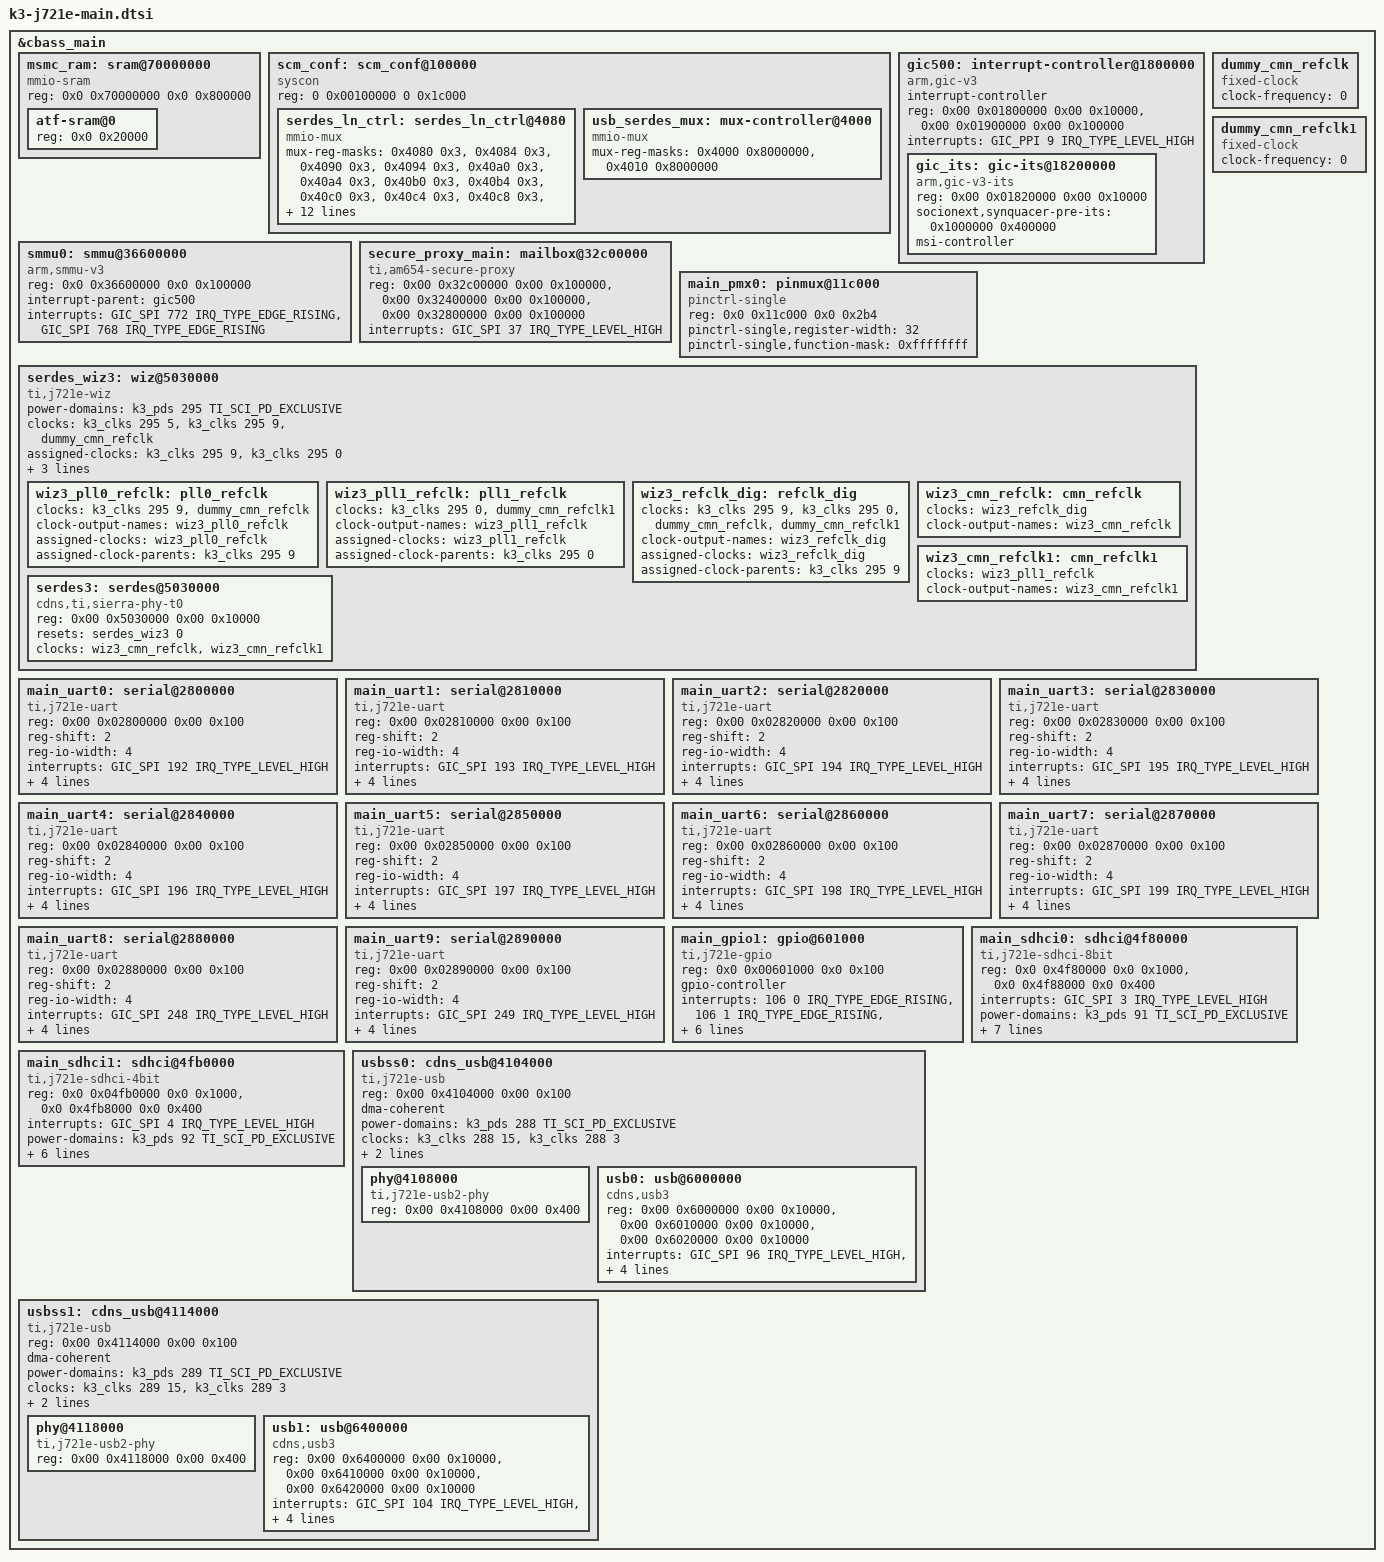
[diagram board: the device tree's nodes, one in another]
// SPDX-License-Identifier: GPL-2.0
/*
 * Device Tree Source for J721E SoC Family Main Domain peripherals
 *
 * Copyright (C) 2016-2019 Texas Instruments Incorporated - http://www.ti.com/
 */
#include <dt-bindings/mux/mux.h>
#include <dt-bindings/phy/phy.h>
#include <dt-bindings/mux/mux-j721e-wiz.h>

&cbass_main {
	msmc_ram: sram@70000000 {
		compatible = "mmio-sram";
		reg = <0x0 0x70000000 0x0 0x800000>;
		#address-cells = <1>;
		#size-cells = <1>;
		ranges = <0x0 0x0 0x70000000 0x800000>;

		atf-sram@0 {
			reg = <0x0 0x20000>;
		};
	};

	scm_conf: scm_conf@100000 {
		compatible = "syscon", "simple-mfd";
		reg = <0 0x00100000 0 0x1c000>;
		#address-cells = <1>;
		#size-cells = <1>;
		ranges = <0x0 0x0 0x00100000 0x1c000>;

		serdes_ln_ctrl: serdes_ln_ctrl@4080 {
			compatible = "mmio-mux";
			#mux-control-cells = <1>;
			mux-reg-masks = <0x4080 0x3>, <0x4084 0x3>, /* SERDES0 lane0/1 select */
					<0x4090 0x3>, <0x4094 0x3>, /* SERDES1 lane0/1 select */
					<0x40a0 0x3>, <0x40a4 0x3>, /* SERDES2 lane0/1 select */
					<0x40b0 0x3>, <0x40b4 0x3>, /* SERDES3 lane0/1 select */
					<0x40c0 0x3>, <0x40c4 0x3>, <0x40c8 0x3>, <0x40cc 0x3>;
					/* SERDES4 lane0/1/2/3 select */
			idle-states = <SERDES0_LANE0_PCIE0_LANE0>, <SERDES0_LANE1_PCIE0_LANE1>,
				      <SERDES1_LANE0_PCIE1_LANE0>, <SERDES1_LANE1_PCIE1_LANE1>,
				      <SERDES2_LANE0_PCIE2_LANE0>, <SERDES2_LANE1_PCIE2_LANE1>,
				      <MUX_IDLE_AS_IS>, <SERDES3_LANE1_USB3_0>,
				      <SERDES4_LANE0_EDP_LANE0>, <SERDES4_LANE1_EDP_LANE1>, <SERDES4_LANE2_EDP_LANE2>, <SERDES4_LANE3_EDP_LANE3>;
		};

		usb_serdes_mux: mux-controller@4000 {
			compatible = "mmio-mux";
			#mux-control-cells = <1>;
			mux-reg-masks = <0x4000 0x8000000>, /* USB0 to SERDES0/3 mux */
					<0x4010 0x8000000>; /* USB1 to SERDES1/2 mux */
	    };
	};

	gic500: interrupt-controller@1800000 {
		compatible = "arm,gic-v3";
		#address-cells = <2>;
		#size-cells = <2>;
		ranges;
		#interrupt-cells = <3>;
		interrupt-controller;
		reg = <0x00 0x01800000 0x00 0x10000>,	/* GICD */
		      <0x00 0x01900000 0x00 0x100000>;	/* GICR */

		/* vcpumntirq: virtual CPU interface maintenance interrupt */
		interrupts = <GIC_PPI 9 IRQ_TYPE_LEVEL_HIGH>;

		gic_its: gic-its@18200000 {
			compatible = "arm,gic-v3-its";
			reg = <0x00 0x01820000 0x00 0x10000>;
			socionext,synquacer-pre-its = <0x1000000 0x400000>;
			msi-controller;
			#msi-cells = <1>;
		};
	};

	smmu0: smmu@36600000 {
		compatible = "arm,smmu-v3";
		reg = <0x0 0x36600000 0x0 0x100000>;
		interrupt-parent = <&gic500>;
		interrupts = <GIC_SPI 772 IRQ_TYPE_EDGE_RISING>,
			     <GIC_SPI 768 IRQ_TYPE_EDGE_RISING>;
		interrupt-names = "eventq", "gerror";
		#iommu-cells = <1>;
	};

	secure_proxy_main: mailbox@32c00000 {
		compatible = "ti,am654-secure-proxy";
		#mbox-cells = <1>;
		reg-names = "target_data", "rt", "scfg";
		reg = <0x00 0x32c00000 0x00 0x100000>,
		      <0x00 0x32400000 0x00 0x100000>,
		      <0x00 0x32800000 0x00 0x100000>;
		interrupt-names = "rx_011";
		interrupts = <GIC_SPI 37 IRQ_TYPE_LEVEL_HIGH>;
	};

	main_pmx0: pinmux@11c000 {
		compatible = "pinctrl-single";
		/* Proxy 0 addressing */
		reg = <0x0 0x11c000 0x0 0x2b4>;
		#pinctrl-cells = <1>;
		pinctrl-single,register-width = <32>;
		pinctrl-single,function-mask = <0xffffffff>;
	};

	dummy_cmn_refclk: dummy_cmn_refclk {
		#clock-cells = <0>;
		compatible = "fixed-clock";
		clock-frequency = <0>;
	};

	dummy_cmn_refclk1: dummy_cmn_refclk1 {
		#clock-cells = <0>;
		compatible = "fixed-clock";
		clock-frequency = <0>;
	};

	serdes_wiz3: wiz@5030000 {
		compatible = "ti,j721e-wiz";
		#address-cells = <2>;
		#size-cells = <2>;
		power-domains = <&k3_pds 295 TI_SCI_PD_EXCLUSIVE>;
		clocks = <&k3_clks 295 5>, <&k3_clks 295 9>, <&dummy_cmn_refclk>;
		clock-names = "fck", "core_ref_clk", "ext_ref_clk";
		assigned-clocks = <&k3_clks 295 9>, <&k3_clks 295 0>;
		assigned-clock-parents = <&k3_clks 295 13>, <&k3_clks 295 4>;
		num-lanes = <2>;
		#reset-cells = <1>;
		ranges;

		wiz3_pll0_refclk: pll0_refclk {
			clocks = <&k3_clks 295 9>, <&dummy_cmn_refclk>;
			clock-output-names = "wiz3_pll0_refclk";
			#clock-cells = <0>;
			assigned-clocks = <&wiz3_pll0_refclk>;
			assigned-clock-parents = <&k3_clks 295 9>;
		};

		wiz3_pll1_refclk: pll1_refclk {
			clocks = <&k3_clks 295 0>, <&dummy_cmn_refclk1>;
			clock-output-names = "wiz3_pll1_refclk";
			#clock-cells = <0>;
			assigned-clocks = <&wiz3_pll1_refclk>;
			assigned-clock-parents = <&k3_clks 295 0>;
		};

		wiz3_refclk_dig: refclk_dig {
			clocks = <&k3_clks 295 9>, <&k3_clks 295 0>, <&dummy_cmn_refclk>, <&dummy_cmn_refclk1>;
			clock-output-names = "wiz3_refclk_dig";
			#clock-cells = <0>;
			assigned-clocks = <&wiz3_refclk_dig>;
			assigned-clock-parents = <&k3_clks 295 9>;
		};

		wiz3_cmn_refclk: cmn_refclk {
			clocks = <&wiz3_refclk_dig>;
			clock-output-names = "wiz3_cmn_refclk";
			#clock-cells = <0>;
		};

		wiz3_cmn_refclk1: cmn_refclk1 {
			clocks = <&wiz3_pll1_refclk>;
			clock-output-names = "wiz3_cmn_refclk1";
			#clock-cells = <0>;
		};

		serdes3: serdes@5030000 {
			compatible = "cdns,ti,sierra-phy-t0";
			reg-names = "serdes";
			reg = <0x00 0x5030000 0x00 0x10000>;
			#address-cells = <1>;
			#size-cells = <0>;
			resets = <&serdes_wiz3 0>;
			reset-names = "sierra_reset";
			clocks = <&wiz3_cmn_refclk>, <&wiz3_cmn_refclk1>;
			clock-names = "cmn_refclk", "cmn_refclk1";
		};
	};

	main_uart0: serial@2800000 {
		compatible = "ti,j721e-uart", "ti,am654-uart";
		reg = <0x00 0x02800000 0x00 0x100>;
		reg-shift = <2>;
		reg-io-width = <4>;
		interrupts = <GIC_SPI 192 IRQ_TYPE_LEVEL_HIGH>;
		clock-frequency = <48000000>;
		current-speed = <115200>;
		power-domains = <&k3_pds 146 TI_SCI_PD_EXCLUSIVE>;
		clocks = <&k3_clks 146 0>;
		clock-names = "fclk";
	};

	main_uart1: serial@2810000 {
		compatible = "ti,j721e-uart", "ti,am654-uart";
		reg = <0x00 0x02810000 0x00 0x100>;
		reg-shift = <2>;
		reg-io-width = <4>;
		interrupts = <GIC_SPI 193 IRQ_TYPE_LEVEL_HIGH>;
		clock-frequency = <48000000>;
		current-speed = <115200>;
		power-domains = <&k3_pds 278 TI_SCI_PD_EXCLUSIVE>;
		clocks = <&k3_clks 278 0>;
		clock-names = "fclk";
	};

	main_uart2: serial@2820000 {
		compatible = "ti,j721e-uart", "ti,am654-uart";
		reg = <0x00 0x02820000 0x00 0x100>;
		reg-shift = <2>;
		reg-io-width = <4>;
		interrupts = <GIC_SPI 194 IRQ_TYPE_LEVEL_HIGH>;
		clock-frequency = <48000000>;
		current-speed = <115200>;
		power-domains = <&k3_pds 279 TI_SCI_PD_EXCLUSIVE>;
		clocks = <&k3_clks 279 0>;
		clock-names = "fclk";
	};

	main_uart3: serial@2830000 {
		compatible = "ti,j721e-uart", "ti,am654-uart";
		reg = <0x00 0x02830000 0x00 0x100>;
		reg-shift = <2>;
		reg-io-width = <4>;
		interrupts = <GIC_SPI 195 IRQ_TYPE_LEVEL_HIGH>;
		clock-frequency = <48000000>;
		current-speed = <115200>;
		power-domains = <&k3_pds 280 TI_SCI_PD_EXCLUSIVE>;
		clocks = <&k3_clks 280 0>;
		clock-names = "fclk";
	};

	main_uart4: serial@2840000 {
		compatible = "ti,j721e-uart", "ti,am654-uart";
		reg = <0x00 0x02840000 0x00 0x100>;
		reg-shift = <2>;
		reg-io-width = <4>;
		interrupts = <GIC_SPI 196 IRQ_TYPE_LEVEL_HIGH>;
		clock-frequency = <48000000>;
		current-speed = <115200>;
		power-domains = <&k3_pds 281 TI_SCI_PD_EXCLUSIVE>;
		clocks = <&k3_clks 281 0>;
		clock-names = "fclk";
	};

	main_uart5: serial@2850000 {
		compatible = "ti,j721e-uart", "ti,am654-uart";
		reg = <0x00 0x02850000 0x00 0x100>;
		reg-shift = <2>;
		reg-io-width = <4>;
		interrupts = <GIC_SPI 197 IRQ_TYPE_LEVEL_HIGH>;
		clock-frequency = <48000000>;
		current-speed = <115200>;
		power-domains = <&k3_pds 282 TI_SCI_PD_EXCLUSIVE>;
		clocks = <&k3_clks 282 0>;
		clock-names = "fclk";
	};

	main_uart6: serial@2860000 {
		compatible = "ti,j721e-uart", "ti,am654-uart";
		reg = <0x00 0x02860000 0x00 0x100>;
		reg-shift = <2>;
		reg-io-width = <4>;
		interrupts = <GIC_SPI 198 IRQ_TYPE_LEVEL_HIGH>;
		clock-frequency = <48000000>;
		current-speed = <115200>;
		power-domains = <&k3_pds 283 TI_SCI_PD_EXCLUSIVE>;
		clocks = <&k3_clks 283 0>;
		clock-names = "fclk";
	};

	main_uart7: serial@2870000 {
		compatible = "ti,j721e-uart", "ti,am654-uart";
		reg = <0x00 0x02870000 0x00 0x100>;
		reg-shift = <2>;
		reg-io-width = <4>;
		interrupts = <GIC_SPI 199 IRQ_TYPE_LEVEL_HIGH>;
		clock-frequency = <48000000>;
		current-speed = <115200>;
		power-domains = <&k3_pds 284 TI_SCI_PD_EXCLUSIVE>;
		clocks = <&k3_clks 284 0>;
		clock-names = "fclk";
	};

	main_uart8: serial@2880000 {
		compatible = "ti,j721e-uart", "ti,am654-uart";
		reg = <0x00 0x02880000 0x00 0x100>;
		reg-shift = <2>;
		reg-io-width = <4>;
		interrupts = <GIC_SPI 248 IRQ_TYPE_LEVEL_HIGH>;
		clock-frequency = <48000000>;
		current-speed = <115200>;
		power-domains = <&k3_pds 285 TI_SCI_PD_EXCLUSIVE>;
		clocks = <&k3_clks 285 0>;
		clock-names = "fclk";
	};

	main_uart9: serial@2890000 {
		compatible = "ti,j721e-uart", "ti,am654-uart";
		reg = <0x00 0x02890000 0x00 0x100>;
		reg-shift = <2>;
		reg-io-width = <4>;
		interrupts = <GIC_SPI 249 IRQ_TYPE_LEVEL_HIGH>;
		clock-frequency = <48000000>;
		current-speed = <115200>;
		power-domains = <&k3_pds 286 TI_SCI_PD_EXCLUSIVE>;
		clocks = <&k3_clks 286 0>;
		clock-names = "fclk";
	};

	main_gpio1: gpio@601000 {
		compatible = "ti,j721e-gpio", "ti,keystone-gpio";
		reg = <0x0 0x00601000 0x0 0x100>;
		gpio-controller;
		#gpio-cells = <2>;
//		interrupt-parent = <&main_gpio_intr>;
		interrupts = <106 0 IRQ_TYPE_EDGE_RISING>,
			     <106 1 IRQ_TYPE_EDGE_RISING>,
			     <106 2 IRQ_TYPE_EDGE_RISING>;
		interrupt-controller;
		#interrupt-cells = <2>;
		ti,ngpio = <36>;
		ti,davinci-gpio-unbanked = <0>;
		power-domains = <&k3_pds 106 TI_SCI_PD_EXCLUSIVE>;
		clocks = <&k3_clks 106 0>;
		clock-names = "gpio";
	};

	main_sdhci0: sdhci@4f80000 {
		compatible = "ti,j721e-sdhci-8bit";
		reg = <0x0 0x4f80000 0x0 0x1000>, <0x0 0x4f88000 0x0 0x400>;
		interrupts = <GIC_SPI 3 IRQ_TYPE_LEVEL_HIGH>;
		power-domains = <&k3_pds 91 TI_SCI_PD_EXCLUSIVE>;
		clock-names = "clk_xin", "clk_ahb";
		clocks = <&k3_clks 91 1>, <&k3_clks 91 0>;
		assigned-clocks = <&k3_clks 91 1>;
		assigned-clock-parents = <&k3_clks 91 2>;
		bus-width = <8>;
		ti,otap-del-sel = <0x2>;
		ti,trm-icp = <0x8>;
		dma-coherent;
	};

	main_sdhci1: sdhci@4fb0000 {
		compatible = "ti,j721e-sdhci-4bit";
		reg = <0x0 0x04fb0000 0x0 0x1000>, <0x0 0x4fb8000 0x0 0x400>;
		interrupts = <GIC_SPI 4 IRQ_TYPE_LEVEL_HIGH>;
		power-domains = <&k3_pds 92 TI_SCI_PD_EXCLUSIVE>;
		clock-names = "clk_xin", "clk_ahb";
		clocks = <&k3_clks 92 0>, <&k3_clks 92 5>;
		assigned-clocks = <&k3_clks 92 0>;
		assigned-clock-parents = <&k3_clks 92 1>;
		ti,otap-del-sel = <0x2>;
		ti,trm-icp = <0x8>;
		dma-coherent;
	};

	usbss0: cdns_usb@4104000 {
		compatible = "ti,j721e-usb";
		reg = <0x00 0x4104000 0x00 0x100>;
		dma-coherent;
		power-domains = <&k3_pds 288 TI_SCI_PD_EXCLUSIVE>;
		clocks = <&k3_clks 288 15>, <&k3_clks 288 3>;
		clock-names = "usb2_refclk", "lpm_clk";
		assigned-clocks = <&k3_clks 288 15>;	/* USB2_REFCLK */
		assigned-clock-parents = <&k3_clks 288 16>; /* HFOSC0 */
		#address-cells = <2>;
		#size-cells = <2>;
		ranges;

		phy@4108000 {
			compatible = "ti,j721e-usb2-phy";
			reg = <0x00 0x4108000 0x00 0x400>;
		};

		usb0: usb@6000000 {
			compatible = "cdns,usb3";
			reg = <0x00 0x6000000 0x00 0x10000>,
			      <0x00 0x6010000 0x00 0x10000>,
			      <0x00 0x6020000 0x00 0x10000>;
			reg-names = "otg", "xhci", "dev";
			interrupts = <GIC_SPI 96 IRQ_TYPE_LEVEL_HIGH>,	/* irq.0 */
				     <GIC_SPI 102 IRQ_TYPE_LEVEL_HIGH>,	/* irq.6 */
				     <GIC_SPI 120 IRQ_TYPE_LEVEL_HIGH>;	/* otgirq.0 */
			interrupt-names = "host",
					  "peripheral",
					  "otg";
			maximum-speed = "super-speed";
			dr_mode = "otg";
		};
	};

	usbss1: cdns_usb@4114000 {
		compatible = "ti,j721e-usb";
		reg = <0x00 0x4114000 0x00 0x100>;
		dma-coherent;
		power-domains = <&k3_pds 289 TI_SCI_PD_EXCLUSIVE>;
		clocks = <&k3_clks 289 15>, <&k3_clks 289 3>;
		clock-names = "usb2_refclk", "lpm_clk";
		assigned-clocks = <&k3_clks 289 15>;	/* USB2_REFCLK */
		assigned-clock-parents = <&k3_clks 289 16>; /* HFOSC0 */
		#address-cells = <2>;
		#size-cells = <2>;
		ranges;

		phy@4118000 {
			compatible = "ti,j721e-usb2-phy";
			reg = <0x00 0x4118000 0x00 0x400>;
		};

		usb1: usb@6400000 {
			compatible = "cdns,usb3";
			reg = <0x00 0x6400000 0x00 0x10000>,
			      <0x00 0x6410000 0x00 0x10000>,
			      <0x00 0x6420000 0x00 0x10000>;
			reg-names = "otg", "xhci", "dev";
			interrupts = <GIC_SPI 104 IRQ_TYPE_LEVEL_HIGH>,	/* irq.0 */
				     <GIC_SPI 110 IRQ_TYPE_LEVEL_HIGH>,	/* irq.6 */
				     <GIC_SPI 121 IRQ_TYPE_LEVEL_HIGH>;	/* otgirq.0 */
			interrupt-names = "host",
					  "peripheral",
					  "otg";
			maximum-speed = "super-speed";
			dr_mode = "otg";
		};
	};
};
